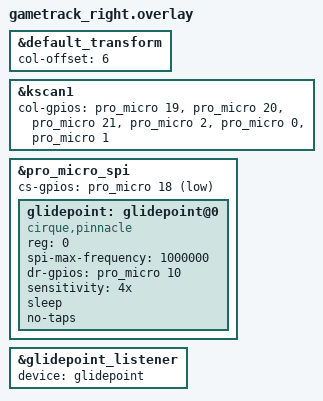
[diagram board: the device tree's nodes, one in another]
#include "gametrack.dtsi"

&default_transform {
    col-offset = <6>;
};

&kscan1 {
    col-gpios
        = <&pro_micro 19 GPIO_ACTIVE_HIGH>
        , <&pro_micro 20 GPIO_ACTIVE_HIGH>
        , <&pro_micro 21 GPIO_ACTIVE_HIGH>
        , <&pro_micro 2 GPIO_ACTIVE_HIGH>
        , <&pro_micro 0 GPIO_ACTIVE_HIGH>
        , <&pro_micro 1 GPIO_ACTIVE_HIGH>
        ;
};

&pro_micro_spi {
    status = "okay";
    cs-gpios = <&pro_micro 18 GPIO_ACTIVE_LOW>;

    glidepoint: glidepoint@0 {
        compatible = "cirque,pinnacle";
        reg = <0>;
        spi-max-frequency = <1000000>;
        status = "okay";
        dr-gpios = <&pro_micro 10 (GPIO_ACTIVE_HIGH)>;

        sensitivity = "4x";
        sleep;
        no-taps;
    };
};

&glidepoint_listener {
    status = "okay";
	  device = <&glidepoint>;
};
